# M037 register map
File version: 2.0.2.2
Registers are 32-bit, read-write, reset 0x0 unless marked. A register's access mark holds for its fields unless they carry their own. Offsets are from the block's base; [hi:lo] are bit positions; {n}, {i} and the like mark numbered series.

## TB0 — 16-bit Timer_Event Counter (TB)
Base 0x400C4000
Same registers: TB1 0x400C4100, TB2 0x400C4200, TB3 0x400C4300, TB4 0x400C4400, TB5 0x400C4500, TB6 0x400C4600, TB7 0x400C4700
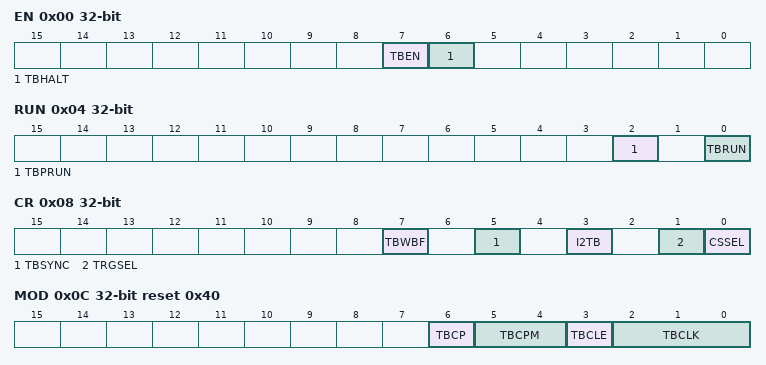
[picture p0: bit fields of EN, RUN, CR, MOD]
0x00 EN — TB Enable Register
  [7] TBEN, [6] TBHALT
0x04 RUN — TB RUN Register
  [2] TBPRUN, [0] TBRUN
0x08 CR — TB Control Register
  [7] TBWBF, [5] TBSYNC, [3] I2TB, [1] TRGSEL, [0] CSSEL
0x0C MOD reset 0x40 — TB Mode Register
  [6] TBCP wo, [5:4] TBCPM, [3] TBCLE, [2:0] TBCLK
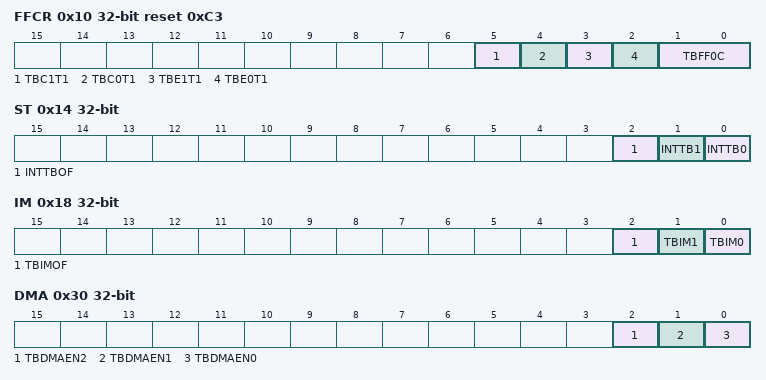
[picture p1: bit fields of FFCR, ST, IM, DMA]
0x10 FFCR reset 0xC3 — TB Flip-Flop Control Register
  [5] TBC1T1, [4] TBC0T1, [3] TBE1T1, [2] TBE0T1, [1:0] TBFF0C
0x14 ST ro — TB Status Register
  [2] INTTBOF, [1] INTTB1, [0] INTTB0
0x18 IM — TB Interrupt Mask Register
  [2] TBIMOF, [1] TBIM1, [0] TBIM0
0x1C UC ro — TB Read Capture Register
  [15:0] TBUC
0x20 RG0 — TB RG0 Timer Register
  [15:0] TBRG0
0x24 RG1 — TB RG1 Timer Register
  [15:0] TBRG1
0x28 CP0 ro (reset mask 0xFFFF0000) — TB CP0 Capture Register
  [15:0] TBCP0
0x2C CP1 ro (reset mask 0xFFFF0000) — TB CP1 Capture Register
  [15:0] TBCP1
0x30 DMA — TB DMA Enable Register
  [2] TBDMAEN2, [1] TBDMAEN1, [0] TBDMAEN0

## SC0 — SC
Base 0x400E1000
Same registers: SC1 0x400E1100, SC2 0x400E1200, SC3 0x400E1300, SC4 0x400E1400
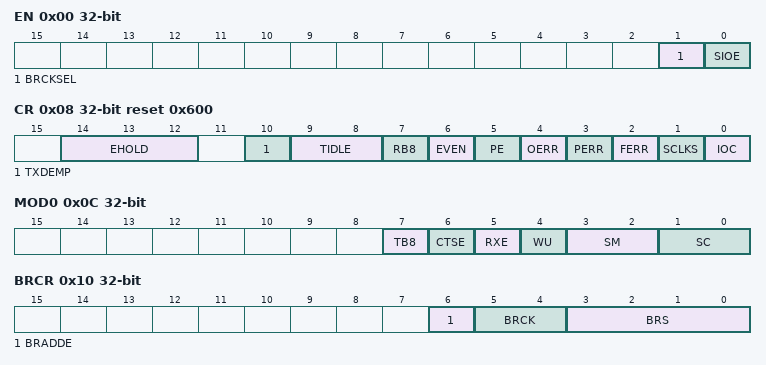
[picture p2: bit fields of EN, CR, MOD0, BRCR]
0x00 EN — SC Enable Register
  [1] BRCKSEL, [0] SIOE
0x04 BUF — SC Buffer Register
  [7:0] TB_RB
0x08 CR reset 0x600 — SC Control Register
  [14:12] EHOLD, [10] TXDEMP, [9:8] TIDLE, [7] RB8 ro, [6] EVEN, [5] PE, [4] OERR ro, [3] PERR ro, [2] FERR ro, [1] SCLKS, [0] IOC
0x0C MOD0 — SC Mode Control Register 0
  [7] TB8, [6] CTSE, [5] RXE, [4] WU, [3:2] SM, [1:0] SC
0x10 BRCR — SC Baud Rate Generator Control Register
  [6] BRADDE, [5:4] BRCK, [3:0] BRS
0x14 BRADD — SC Baud Rate Generator Control Register 2
  [3:0] BRK
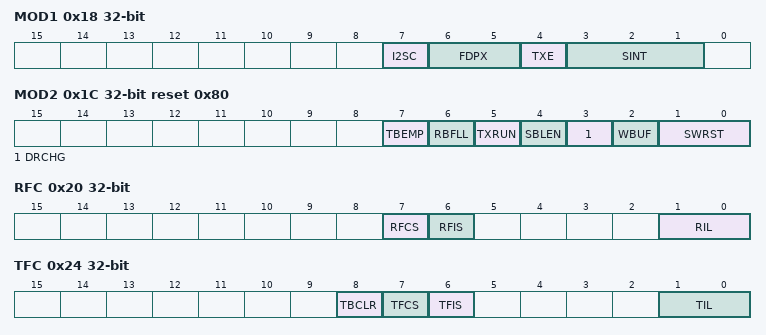
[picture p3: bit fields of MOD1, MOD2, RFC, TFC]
0x18 MOD1 — SC Mode Control Register 1
  [7] I2SC, [6:5] FDPX, [4] TXE, [3:1] SINT
0x1C MOD2 reset 0x80 — SC Mode Control Register 2
  [7] TBEMP ro, [6] RBFLL ro, [5] TXRUN ro, [4] SBLEN, [3] DRCHG, [2] WBUF, [1:0] SWRST
0x20 RFC — SC RX FIFO Configuration Register
  [7] RFCS wo, [6] RFIS, [1:0] RIL
0x24 TFC — SC TX FIFO Configuration Register
  [8] TBCLR wo, [7] TFCS wo, [6] TFIS, [1:0] TIL
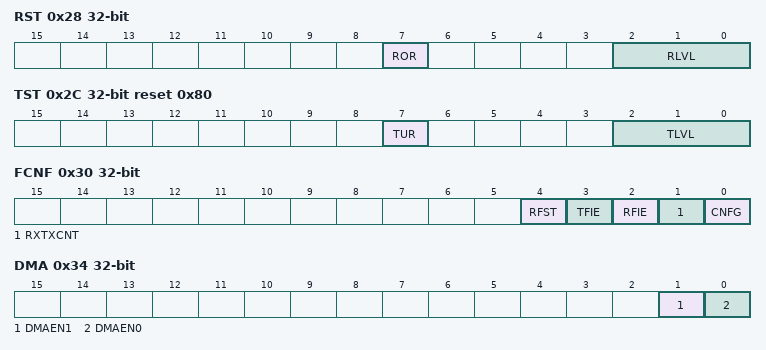
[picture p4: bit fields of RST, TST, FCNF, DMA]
0x28 RST ro — SC RX FIFO Status Register
  [7] ROR, [2:0] RLVL
0x2C TST ro reset 0x80 — SC TX FIFO Status Register
  [7] TUR, [2:0] TLVL
0x30 FCNF — SC FIFO Configuration Register
  [4] RFST, [3] TFIE, [2] RFIE, [1] RXTXCNT, [0] CNFG
0x34 DMA — SC DMA Request Register
  [1] DMAEN1, [0] DMAEN0

## WD — WDT
Base 0x400F2000
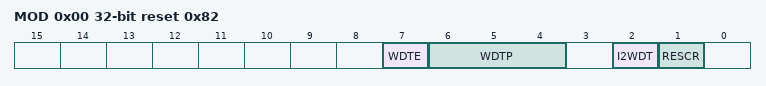
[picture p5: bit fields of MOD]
0x00 MOD reset 0x82 — WD Mode Register
  [7] WDTE, [6:4] WDTP, [2] I2WDT, [1] RESCR
0x04 CR wo (reset mask 0xFFFFFF00) — WD Control Register
  [7:0] WDCR

## CG
Base 0x400F3000
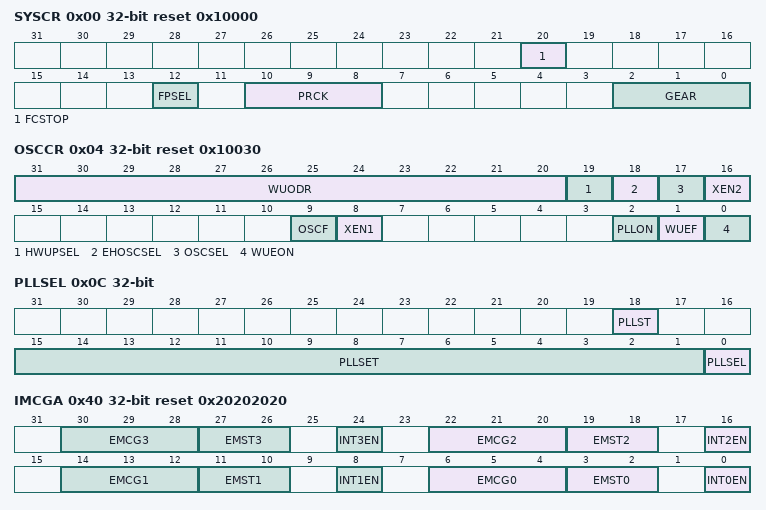
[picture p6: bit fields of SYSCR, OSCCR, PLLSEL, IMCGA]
0x00 SYSCR reset 0x10000 — System Control Register
  [20] FCSTOP, [12] FPSEL, [10:8] PRCK, [2:0] GEAR
0x04 OSCCR reset 0x10030 — Oscillation Control Register
  [31:20] WUODR, [19] HWUPSEL, [18] EHOSCSEL, [17] OSCSEL, [16] XEN2, [9] OSCF ro, [8] XEN1, [2] PLLON, [1] WUEF ro, [0] WUEON wo
0x08 STBYCR reset 0x103 — Standby Control Register
  [2:0] STBY
0x0C PLLSEL — PLL Selection Register
  [18] PLLST ro, [15:1] PLLSET, [0] PLLSEL
0x3C PROTECT reset 0xC1
  [7:0] CGPROTECT
0x40 IMCGA reset 0x20202020 — CG Interrupt Mode Control Register A
  [8n+6:8n+4] EMCG{n} (n=0..3), [8n+3:8n+2] EMST{n} ro (n=0..3), [8n] INT{n}EN (n=0..3)
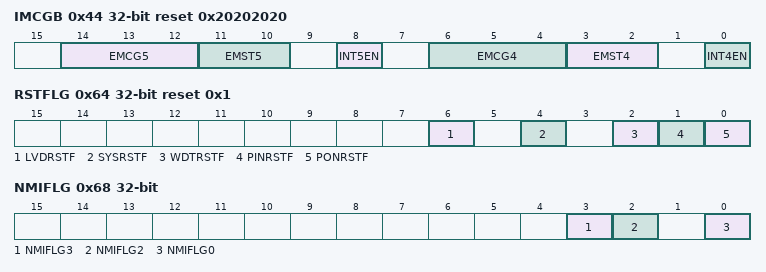
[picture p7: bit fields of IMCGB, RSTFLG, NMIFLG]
0x44 IMCGB reset 0x20202020 — CG Interrupt Mode Control Register B
  [14:12] EMCG5, [11:10] EMST5 ro, [8] INT5EN, [6:4] EMCG4, [3:2] EMST4 ro, [0] INT4EN
0x60 ICRCG wo — CG Interrupt Request Clear Register
  [4:0] ICRCG
0x64 RSTFLG reset 0x1 (reset mask 0xFFFFFF99) — Reset Flag Register
  [6] LVDRSTF, [4] SYSRSTF, [2] WDTRSTF, [1] PINRSTF, [0] PONRSTF
0x68 NMIFLG ro — NMI Flag Register
  [3] NMIFLG3, [2] NMIFLG2, [0] NMIFLG0

## LVD
Base 0x400F4000
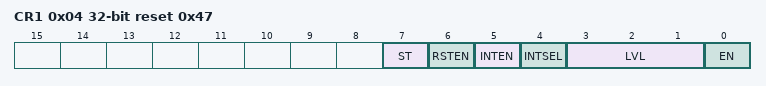
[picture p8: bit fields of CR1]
0x04 CR1 reset 0x47 — LVD Control register
  [7] ST ro, [6] RSTEN, [5] INTEN, [4] INTSEL, [3:1] LVL, [0] EN

## AD — ADC
Base 0x400FC000
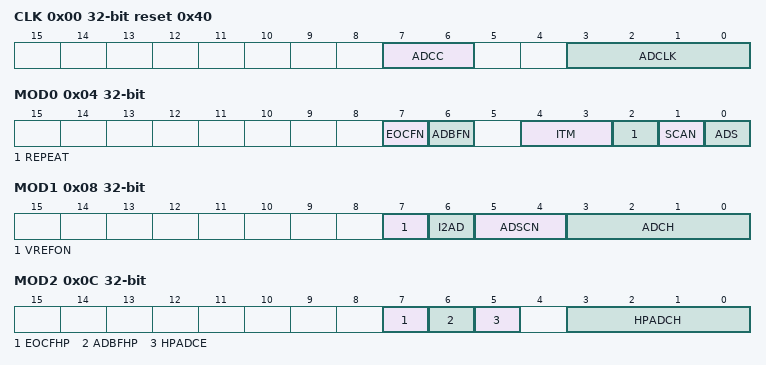
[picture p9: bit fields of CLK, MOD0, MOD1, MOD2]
0x00 CLK reset 0x40 — AD Conversion Clock Setting Register
  [7:6] ADCC, [3:0] ADCLK
0x04 MOD0 — AD Mode Control Register 0
  [7] EOCFN ro, [6] ADBFN ro, [4:3] ITM, [2] REPEAT, [1] SCAN, [0] ADS wo
0x08 MOD1 — AD Mode Control Register 1
  [7] VREFON, [6] I2AD, [5:4] ADSCN, [3:0] ADCH
0x0C MOD2 — AD Mode Control Register 2
  [7] EOCFHP ro, [6] ADBFHP ro, [5] HPADCE wo, [3:0] HPADCH
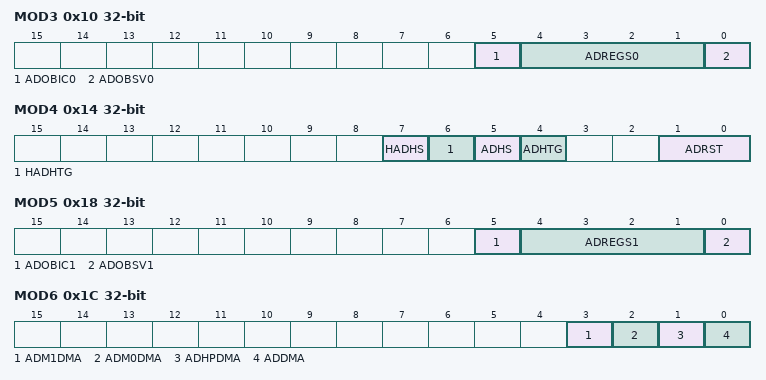
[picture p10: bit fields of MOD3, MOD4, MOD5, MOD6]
0x10 MOD3 — AD Mode Control Register 3
  [5] ADOBIC0, [4:1] ADREGS0, [0] ADOBSV0
0x14 MOD4 — AD Mode Control Register 4
  [7] HADHS, [6] HADHTG, [5] ADHS, [4] ADHTG, [1:0] ADRST wo
0x18 MOD5 — AD Mode Control Register 5
  [5] ADOBIC1, [4:1] ADREGS1, [0] ADOBSV1
0x1C MOD6 — AD Mode Control Register 6
  [3] ADM1DMA, [2] ADM0DMA, [1] ADHPDMA, [0] ADDMA
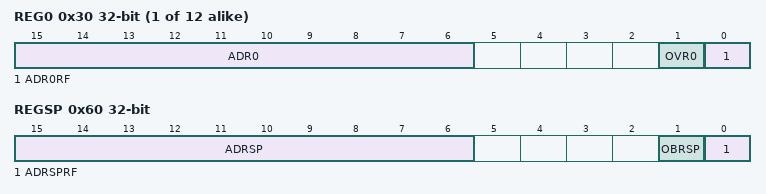
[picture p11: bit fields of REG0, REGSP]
{0x30+4i} REG{i} ro (i=0..11) — AD Conversion Result Register {i}
  [15:6] ADR{i}, [1] OVR{i}, [0] ADR{i}RF
0x60 REGSP ro — AD Conversion Result Register SP
  [15:6] ADRSP, [1] OBRSP, [0] ADRSPRF
0x64 CMP0 — AD Conversion Result comparing register0
  [15:6] ADCOM0
0x68 CMP1 — AD Conversion result comparing register1
  [15:6] ADCOM1

## FC
Base 0x41FFF000
0x10 SECBIT reset 0x1 — FC Security Bit Register
  [0] SECBIT
0x20 SR ro reset 0x1 — FC Flash Status Register
  [0] RDY_BSY
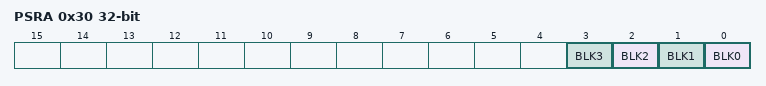
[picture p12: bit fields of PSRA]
0x30 PSRA ro (reset mask 0xFFFFFFF0) — FC Protect status register
  [n] BLK{n} (n=0..3)
